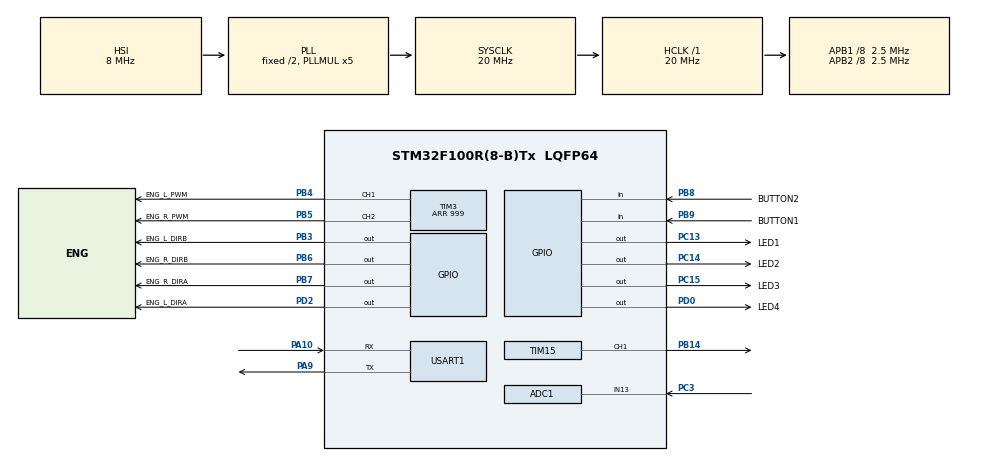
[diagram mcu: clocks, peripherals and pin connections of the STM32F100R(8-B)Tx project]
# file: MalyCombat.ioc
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ADC1.Channel-0\#ChannelRegularConversion=ADC_CHANNEL_13
ADC1.NbrOfConversionFlag=1
ADC1.Rank-0\#ChannelRegularConversion=1
ADC1.SamplingTime-0\#ChannelRegularConversion=ADC_SAMPLETIME_1CYCLE_5
ADC1.master=1
Dma.Request0=USART1_RX
Dma.USART1_RX.0.Direction=DMA_PERIPH_TO_MEMORY
Dma.USART1_RX.0.Instance=DMA1_Channel5
Dma.USART1_RX.0.MemDataAlignment=DMA_MDATAALIGN_BYTE
Dma.USART1_RX.0.MemInc=DMA_MINC_ENABLE
Dma.USART1_RX.0.Mode=DMA_CIRCULAR
Dma.USART1_RX.0.PeriphDataAlignment=DMA_PDATAALIGN_BYTE
Dma.USART1_RX.0.PeriphInc=DMA_PINC_DISABLE
Dma.USART1_RX.0.Priority=DMA_PRIORITY_LOW
Mcu.Family=STM32F1
Mcu.Name=STM32F100R(8-B)Tx
Mcu.Package=LQFP64
NVIC.DMA1_Channel5_IRQn=true\:0\:0\:false\:false\:true\:false
NVIC.PriorityGroup=NVIC_PRIORITYGROUP_4
PA10.Mode=Asynchronous
PA10.Signal=USART1_RX
PA13.Mode=Serial_Wire
PA13.Signal=SYS_JTMS-SWDIO
PA14.Mode=Serial_Wire
PA14.Signal=SYS_JTCK-SWCLK
PA9.Mode=Asynchronous
PA9.Signal=USART1_TX
PB14.Signal=S_TIM15_CH1
PB3.GPIO_Label=ENG_L_DIRB
PB3.Signal=GPIO_Output
PB4.GPIO_Label=ENG_L_PWM
PB4.Signal=S_TIM3_CH1
PB5.GPIO_Label=ENG_R_PWM
PB5.Signal=S_TIM3_CH2
PB6.GPIO_Label=ENG_R_DIRB
PB6.Signal=GPIO_Output
PB7.GPIO_Label=ENG_R_DIRA
PB7.Signal=GPIO_Output
PB8.GPIO_Label=BUTTON2
PB8.Signal=GPIO_Input
PB9.GPIO_Label=BUTTON1
PB9.Signal=GPIO_Input
PC13-TAMPER-RTC.GPIO_Label=LED1
PC13-TAMPER-RTC.Signal=GPIO_Output
PC14-OSC32_IN.GPIO_Label=LED2
PC14-OSC32_IN.Signal=GPIO_Output
PC15-OSC32_OUT.GPIO_Label=LED3
PC15-OSC32_OUT.Signal=GPIO_Output
PC3.Signal=ADCx_IN13
PD0-OSC_IN.GPIO_Label=LED4
PD0-OSC_IN.Signal=GPIO_Output
PD2.GPIO_Label=ENG_L_DIRA
PD2.Signal=GPIO_Output
ProjectManager.HeapSize=0x200
ProjectManager.StackSize=0x400
ProjectManager.TargetToolchain=TrueSTUDIO
RCC.AHBFreq_Value=20000000
RCC.APB1CLKDivider=RCC_HCLK_DIV8
RCC.APB1Freq_Value=2500000
RCC.APB1TimFreq_Value=5000000
RCC.APB2CLKDivider=RCC_HCLK_DIV8
RCC.APB2Freq_Value=2500000
RCC.APB2TimFreq_Value=5000000
RCC.HCLKFreq_Value=20000000
RCC.PLLMUL=RCC_PLL_MUL5
RCC.SYSCLKFreq_VALUE=20000000
RCC.SYSCLKSource=RCC_SYSCLKSOURCE_PLLCLK
SH.ADCx_IN13.0=ADC1_IN13,IN13
SH.S_TIM15_CH1.0=TIM15_CH1,PWM Generation1 CH1
SH.S_TIM3_CH1.0=TIM3_CH1,PWM Generation1 CH1
SH.S_TIM3_CH2.0=TIM3_CH2,PWM Generation2 CH2
TIM15.Channel-PWM\ Generation1\ CH1=TIM_CHANNEL_1
TIM15.Period=49999
TIM15.Prescaler=1
TIM3.Channel-PWM\ Generation1\ CH1=TIM_CHANNEL_1
TIM3.Channel-PWM\ Generation2\ CH2=TIM_CHANNEL_2
TIM3.Period=999
USART1.VirtualMode=VM_ASYNC
VP_TIM3_VS_ClockSourceINT.Mode=Internal
board=custom

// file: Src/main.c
/* USER CODE BEGIN Header */
/**
  ******************************************************************************
  * @file           : main.c
  * @brief          : Main program body
  ******************************************************************************
  ** This notice applies to any and all portions of this file
  * that are not between comment pairs USER CODE BEGIN and
  * USER CODE END. Other portions of this file, whether
  * inserted by the user or by software development tools
  * are owned by their respective copyright owners.
  *
  * COPYRIGHT(c) 2019 STMicroelectronics
  *
  * Redistribution and use in source and binary forms, with or without modification,
  * are permitted provided that the following conditions are met:
  *   1. Redistributions of source code must retain the above copyright notice,
  *      this list of conditions and the following disclaimer.
  *   2. Redistributions in binary form must reproduce the above copyright notice,
  *      this list of conditions and the following disclaimer in the documentation
  *      and/or other materials provided with the distribution.
  *   3. Neither the name of STMicroelectronics nor the names of its contributors
  *      may be used to endorse or promote products derived from this software
  *      without specific prior written permission.
  *
  * THIS SOFTWARE IS PROVIDED BY THE COPYRIGHT HOLDERS AND CONTRIBUTORS "AS IS"
  * AND ANY EXPRESS OR IMPLIED WARRANTIES, INCLUDING, BUT NOT LIMITED TO, THE
  * IMPLIED WARRANTIES OF MERCHANTABILITY AND FITNESS FOR A PARTICULAR PURPOSE ARE
  * DISCLAIMED. IN NO EVENT SHALL THE COPYRIGHT HOLDER OR CONTRIBUTORS BE LIABLE
  * FOR ANY DIRECT, INDIRECT, INCIDENTAL, SPECIAL, EXEMPLARY, OR CONSEQUENTIAL
  * DAMAGES (INCLUDING, BUT NOT LIMITED TO, PROCUREMENT OF SUBSTITUTE GOODS OR
  * SERVICES; LOSS OF USE, DATA, OR PROFITS; OR BUSINESS INTERRUPTION) HOWEVER
  * CAUSED AND ON ANY THEORY OF LIABILITY, WHETHER IN CONTRACT, STRICT LIABILITY,
  * OR TORT (INCLUDING NEGLIGENCE OR OTHERWISE) ARISING IN ANY WAY OUT OF THE USE
  * OF THIS SOFTWARE, EVEN IF ADVISED OF THE POSSIBILITY OF SUCH DAMAGE.
  *
  ******************************************************************************
  */
/* USER CODE END Header */

#include "main.h"

/* USER CODE BEGIN Includes */
#include "userMain.h"

/* USER CODE END Includes */

ADC_HandleTypeDef hadc1;

TIM_HandleTypeDef htim3;
TIM_HandleTypeDef htim15;

UART_HandleTypeDef huart1;
DMA_HandleTypeDef hdma_usart1_rx;

void SystemClock_Config(void);
static void MX_GPIO_Init(void);
static void MX_DMA_Init(void);
static void MX_ADC1_Init(void);
static void MX_TIM3_Init(void);
static void MX_TIM15_Init(void);
static void MX_USART1_UART_Init(void);

int main(void)
{

  /* MCU Configuration--------------------------------------------------------*/

  /* Reset of all peripherals, Initializes the Flash interface and the Systick. */
  HAL_Init();

  /* Configure the system clock */
  SystemClock_Config();

  /* Initialize all configured peripherals */
  MX_GPIO_Init();
  MX_DMA_Init();
  MX_ADC1_Init();
  MX_TIM3_Init();
  MX_TIM15_Init();
  MX_USART1_UART_Init();
  /* USER CODE BEGIN 2 */
  userMain();
//	HAL_GPIO_WritePin(LED1_GPIO_Port, LED1_Pin, 1);
  /* USER CODE END 2 */

  /* Infinite loop */
  while (1)
  {

  }
}

void SystemClock_Config(void)
{
  RCC_OscInitTypeDef RCC_OscInitStruct = {0};
  RCC_ClkInitTypeDef RCC_ClkInitStruct = {0};
  RCC_PeriphCLKInitTypeDef PeriphClkInit = {0};

  /**Initializes the CPU, AHB and APB busses clocks
  */
  RCC_OscInitStruct.OscillatorType = RCC_OSCILLATORTYPE_HSI;
  RCC_OscInitStruct.HSIState = RCC_HSI_ON;
  RCC_OscInitStruct.HSICalibrationValue = RCC_HSICALIBRATION_DEFAULT;
  RCC_OscInitStruct.PLL.PLLState = RCC_PLL_ON;
  RCC_OscInitStruct.PLL.PLLSource = RCC_PLLSOURCE_HSI_DIV2;
  RCC_OscInitStruct.PLL.PLLMUL = RCC_PLL_MUL5;
  if (HAL_RCC_OscConfig(&RCC_OscInitStruct) != HAL_OK)
  {
    Error_Handler();
  }
  /**Initializes the CPU, AHB and APB busses clocks
  */
  RCC_ClkInitStruct.ClockType = RCC_CLOCKTYPE_HCLK|RCC_CLOCKTYPE_SYSCLK
                              |RCC_CLOCKTYPE_PCLK1|RCC_CLOCKTYPE_PCLK2;
  RCC_ClkInitStruct.SYSCLKSource = RCC_SYSCLKSOURCE_PLLCLK;
  RCC_ClkInitStruct.AHBCLKDivider = RCC_SYSCLK_DIV1;
  RCC_ClkInitStruct.APB1CLKDivider = RCC_HCLK_DIV8;
  RCC_ClkInitStruct.APB2CLKDivider = RCC_HCLK_DIV8;

  if (HAL_RCC_ClockConfig(&RCC_ClkInitStruct, FLASH_LATENCY_0) != HAL_OK)
  {
    Error_Handler();
  }
  PeriphClkInit.PeriphClockSelection = RCC_PERIPHCLK_ADC;
  PeriphClkInit.AdcClockSelection = RCC_ADCPCLK2_DIV2;
  if (HAL_RCCEx_PeriphCLKConfig(&PeriphClkInit) != HAL_OK)
  {
    Error_Handler();
  }
}

static void MX_ADC1_Init(void)
{

  ADC_ChannelConfTypeDef sConfig = {0};

  /**Common config
  */
  hadc1.Instance = ADC1;
  hadc1.Init.ScanConvMode = ADC_SCAN_DISABLE;
  hadc1.Init.ContinuousConvMode = DISABLE;
  hadc1.Init.DiscontinuousConvMode = DISABLE;
  hadc1.Init.ExternalTrigConv = ADC_SOFTWARE_START;
  hadc1.Init.DataAlign = ADC_DATAALIGN_RIGHT;
  hadc1.Init.NbrOfConversion = 1;
  if (HAL_ADC_Init(&hadc1) != HAL_OK)
  {
    Error_Handler();
  }
  /**Configure Regular Channel
  */
  sConfig.Channel = ADC_CHANNEL_13;
  sConfig.Rank = ADC_REGULAR_RANK_1;
  sConfig.SamplingTime = ADC_SAMPLETIME_1CYCLE_5;
  if (HAL_ADC_ConfigChannel(&hadc1, &sConfig) != HAL_OK)
  {
    Error_Handler();
  }

}

static void MX_TIM3_Init(void)
{

  TIM_ClockConfigTypeDef sClockSourceConfig = {0};
  TIM_MasterConfigTypeDef sMasterConfig = {0};
  TIM_OC_InitTypeDef sConfigOC = {0};

  htim3.Instance = TIM3;
  htim3.Init.Prescaler = 0;
  htim3.Init.CounterMode = TIM_COUNTERMODE_UP;
  htim3.Init.Period = 999;
  htim3.Init.ClockDivision = TIM_CLOCKDIVISION_DIV1;
  htim3.Init.AutoReloadPreload = TIM_AUTORELOAD_PRELOAD_DISABLE;
  if (HAL_TIM_Base_Init(&htim3) != HAL_OK)
  {
    Error_Handler();
  }
  sClockSourceConfig.ClockSource = TIM_CLOCKSOURCE_INTERNAL;
  if (HAL_TIM_ConfigClockSource(&htim3, &sClockSourceConfig) != HAL_OK)
  {
    Error_Handler();
  }
  if (HAL_TIM_PWM_Init(&htim3) != HAL_OK)
  {
    Error_Handler();
  }
  sMasterConfig.MasterOutputTrigger = TIM_TRGO_RESET;
  sMasterConfig.MasterSlaveMode = TIM_MASTERSLAVEMODE_DISABLE;
  if (HAL_TIMEx_MasterConfigSynchronization(&htim3, &sMasterConfig) != HAL_OK)
  {
    Error_Handler();
  }
  sConfigOC.OCMode = TIM_OCMODE_PWM1;
  sConfigOC.Pulse = 0;
  sConfigOC.OCPolarity = TIM_OCPOLARITY_HIGH;
  sConfigOC.OCFastMode = TIM_OCFAST_DISABLE;
  if (HAL_TIM_PWM_ConfigChannel(&htim3, &sConfigOC, TIM_CHANNEL_1) != HAL_OK)
  {
    Error_Handler();
  }
  if (HAL_TIM_PWM_ConfigChannel(&htim3, &sConfigOC, TIM_CHANNEL_2) != HAL_OK)
  {
    Error_Handler();
  }
  HAL_TIM_MspPostInit(&htim3);

}

static void MX_TIM15_Init(void)
{

  TIM_MasterConfigTypeDef sMasterConfig = {0};
  TIM_OC_InitTypeDef sConfigOC = {0};
  TIM_BreakDeadTimeConfigTypeDef sBreakDeadTimeConfig = {0};

  htim15.Instance = TIM15;
  htim15.Init.Prescaler = 1;
  htim15.Init.CounterMode = TIM_COUNTERMODE_UP;
  htim15.Init.Period = 49999;
  htim15.Init.ClockDivision = TIM_CLOCKDIVISION_DIV1;
  htim15.Init.RepetitionCounter = 0;
  htim15.Init.AutoReloadPreload = TIM_AUTORELOAD_PRELOAD_DISABLE;
  if (HAL_TIM_PWM_Init(&htim15) != HAL_OK)
  {
    Error_Handler();
  }
  sMasterConfig.MasterOutputTrigger = TIM_TRGO_RESET;
  sMasterConfig.MasterSlaveMode = TIM_MASTERSLAVEMODE_DISABLE;
  if (HAL_TIMEx_MasterConfigSynchronization(&htim15, &sMasterConfig) != HAL_OK)
  {
    Error_Handler();
  }
  sConfigOC.OCMode = TIM_OCMODE_PWM1;
  sConfigOC.Pulse = 0;
  sConfigOC.OCPolarity = TIM_OCPOLARITY_HIGH;
  sConfigOC.OCNPolarity = TIM_OCNPOLARITY_HIGH;
  sConfigOC.OCFastMode = TIM_OCFAST_DISABLE;
  sConfigOC.OCIdleState = TIM_OCIDLESTATE_RESET;
  sConfigOC.OCNIdleState = TIM_OCNIDLESTATE_RESET;
  if (HAL_TIM_PWM_ConfigChannel(&htim15, &sConfigOC, TIM_CHANNEL_1) != HAL_OK)
  {
    Error_Handler();
  }
  sBreakDeadTimeConfig.OffStateRunMode = TIM_OSSR_DISABLE;
  sBreakDeadTimeConfig.OffStateIDLEMode = TIM_OSSI_DISABLE;
  sBreakDeadTimeConfig.LockLevel = TIM_LOCKLEVEL_OFF;
  sBreakDeadTimeConfig.DeadTime = 0;
  sBreakDeadTimeConfig.BreakState = TIM_BREAK_DISABLE;
  sBreakDeadTimeConfig.BreakPolarity = TIM_BREAKPOLARITY_HIGH;
  sBreakDeadTimeConfig.AutomaticOutput = TIM_AUTOMATICOUTPUT_DISABLE;
  if (HAL_TIMEx_ConfigBreakDeadTime(&htim15, &sBreakDeadTimeConfig) != HAL_OK)
  {
    Error_Handler();
  }
  HAL_TIM_MspPostInit(&htim15);

}

static void MX_USART1_UART_Init(void)
{

  huart1.Instance = USART1;
  huart1.Init.BaudRate = 115200;
  huart1.Init.WordLength = UART_WORDLENGTH_8B;
  huart1.Init.StopBits = UART_STOPBITS_1;
  huart1.Init.Parity = UART_PARITY_NONE;
  huart1.Init.Mode = UART_MODE_TX_RX;
  huart1.Init.HwFlowCtl = UART_HWCONTROL_NONE;
  huart1.Init.OverSampling = UART_OVERSAMPLING_16;
  if (HAL_UART_Init(&huart1) != HAL_OK)
  {
    Error_Handler();
  }

}

static void MX_DMA_Init(void)
{
  /* DMA controller clock enable */
  __HAL_RCC_DMA1_CLK_ENABLE();

  /* DMA interrupt init */
  /* DMA1_Channel5_IRQn interrupt configuration */
  HAL_NVIC_SetPriority(DMA1_Channel5_IRQn, 0, 0);
  HAL_NVIC_EnableIRQ(DMA1_Channel5_IRQn);

}

static void MX_GPIO_Init(void)
{
  GPIO_InitTypeDef GPIO_InitStruct = {0};

  /* GPIO Ports Clock Enable */
  __HAL_RCC_GPIOC_CLK_ENABLE();
  __HAL_RCC_GPIOD_CLK_ENABLE();
  __HAL_RCC_GPIOB_CLK_ENABLE();
  __HAL_RCC_GPIOA_CLK_ENABLE();

  /*Configure GPIO pin Output Level */
  HAL_GPIO_WritePin(GPIOC, LED1_Pin|LED2_Pin|LED3_Pin, GPIO_PIN_RESET);

  /*Configure GPIO pin Output Level */
  HAL_GPIO_WritePin(GPIOD, LED4_Pin|ENG_L_DIRA_Pin, GPIO_PIN_RESET);

  /*Configure GPIO pin Output Level */
  HAL_GPIO_WritePin(GPIOB, ENG_L_DIRB_Pin|ENG_R_DIRB_Pin|ENG_R_DIRA_Pin, GPIO_PIN_RESET);

  /*Configure GPIO pins : LED1_Pin LED2_Pin LED3_Pin */
  GPIO_InitStruct.Pin = LED1_Pin|LED2_Pin|LED3_Pin;
  GPIO_InitStruct.Mode = GPIO_MODE_OUTPUT_PP;
  GPIO_InitStruct.Pull = GPIO_NOPULL;
  GPIO_InitStruct.Speed = GPIO_SPEED_FREQ_LOW;
  HAL_GPIO_Init(GPIOC, &GPIO_InitStruct);

  /*Configure GPIO pins : LED4_Pin ENG_L_DIRA_Pin */
  GPIO_InitStruct.Pin = LED4_Pin|ENG_L_DIRA_Pin;
  GPIO_InitStruct.Mode = GPIO_MODE_OUTPUT_PP;
  GPIO_InitStruct.Pull = GPIO_NOPULL;
  GPIO_InitStruct.Speed = GPIO_SPEED_FREQ_LOW;
  HAL_GPIO_Init(GPIOD, &GPIO_InitStruct);

  /*Configure GPIO pins : ENG_L_DIRB_Pin ENG_R_DIRB_Pin ENG_R_DIRA_Pin */
  GPIO_InitStruct.Pin = ENG_L_DIRB_Pin|ENG_R_DIRB_Pin|ENG_R_DIRA_Pin;
  GPIO_InitStruct.Mode = GPIO_MODE_OUTPUT_PP;
  GPIO_InitStruct.Pull = GPIO_NOPULL;
  GPIO_InitStruct.Speed = GPIO_SPEED_FREQ_LOW;
  HAL_GPIO_Init(GPIOB, &GPIO_InitStruct);

  /*Configure GPIO pins : BUTTON2_Pin BUTTON1_Pin */
  GPIO_InitStruct.Pin = BUTTON2_Pin|BUTTON1_Pin;
  GPIO_InitStruct.Mode = GPIO_MODE_INPUT;
  GPIO_InitStruct.Pull = GPIO_NOPULL;
  HAL_GPIO_Init(GPIOB, &GPIO_InitStruct);

  /*Configure peripheral I/O remapping */
  __HAL_AFIO_REMAP_PD01_ENABLE();

}

void Error_Handler(void)
{
}

/************************ (C) COPYRIGHT STMicroelectronics *****END OF FILE****/
